# UART5 register map
Registers from a debugger description file.
Registers are 32-bit, access not given, no defined reset value unless marked. A register's access mark holds for its fields unless they carry their own. Addresses are absolute; registers are grouped by the start of their names; lines under a group give offsets from that group; [hi:lo] are bit positions; {n}, {i} and the like mark numbered series; 'fields as' and 'values as' point back to an identical list; <NAME> marks a mode.

## UART5
0x50001000 UART5/DLL
  [7:0] DLL
0x50001000 UART5/THR
  [7:0] THR
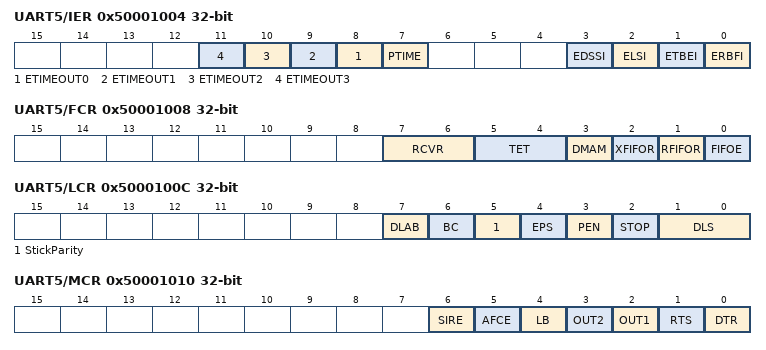
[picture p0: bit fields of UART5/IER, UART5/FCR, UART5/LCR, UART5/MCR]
0x50001004 UART5/IER
  [n+8] ETIMEOUT{n} (n=0..3), [7] PTIME, [3] EDSSI, [2] ELSI, [1] ETBEI, [0] ERBFI
0x50001004 UART5/DLH
  [7:0] DLH
0x50001008 UART5/FCR
  [7:6] RCVR, [5:4] TET, [3] DMAM, [2] XFIFOR, [1] RFIFOR, [0] FIFOE
0x5000100C UART5/LCR
  [7] DLAB, [6] BC, [5] StickParity, [4] EPS, [3] PEN, [2] STOP, [1:0] DLS
0x50001010 UART5/MCR
  [6] SIRE, [5] AFCE, [4] LB, [3] OUT2, [2] OUT1, [1] RTS, [0] DTR
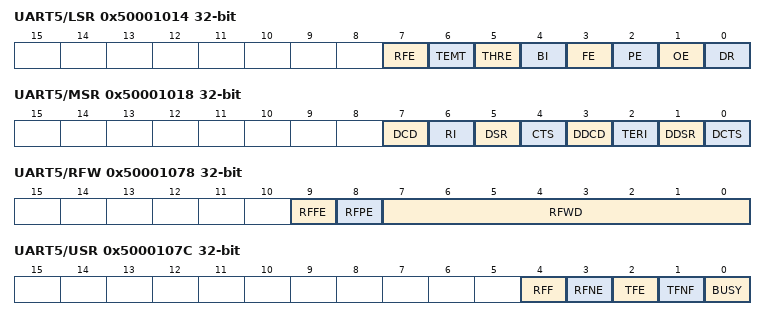
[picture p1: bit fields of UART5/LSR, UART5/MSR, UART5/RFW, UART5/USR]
0x50001014 UART5/LSR ro
  [7] RFE, [6] TEMT, [5] THRE, [4] BI, [3] FE, [2] PE, [1] OE, [0] DR
0x50001018 UART5/MSR ro
  [7] DCD, [6] RI, [5] DSR, [4] CTS, [3] DDCD, [2] TERI, [1] DDSR, [0] DCTS
0x5000101C UART5/SCR
  [7:0] SCR
0x50001030 UART5/STHR
  [7:0] STHR
0x50001070 UART5/FAR
  [0] FAR
0x50001074 UART5/TFR ro
  [7:0] TFR
0x50001078 UART5/RFW
  [9] RFFE, [8] RFPE, [7:0] RFWD
0x5000107C UART5/USR ro
  [4] RFF, [3] RFNE, [2] TFE, [1] TFNF, [0] BUSY
0x50001080 UART5/TFL ro
  [4:0] TFL
0x50001084 UART5/RFL ro
  [4:0] RFL
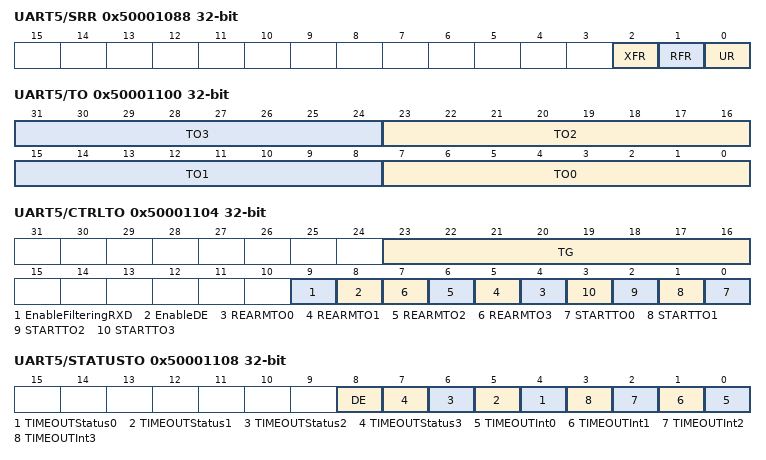
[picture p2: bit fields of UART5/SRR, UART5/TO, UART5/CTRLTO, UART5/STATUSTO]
0x50001088 UART5/SRR
  [2] XFR, [1] RFR, [0] UR
0x5000108C UART5/SRTS
  [0] SRTS
0x50001090 UART5/SBCR
  [0] SBCR
0x50001098 UART5/SFE
  [0] SFE
0x5000109C UART5/SRT
  [1:0] SRCVR
0x500010A0 UART5/STET
  [1:0] STET
0x500010A4 UART5/HTX
  [0] HTX
0x500010A8 UART5/DMASA
  [0] DMASA
0x500010F8 UART5/UCV ro
  [31:0] Version
0x500010FC UART5/CTR ro
  [31:0] ID
0x50001100 UART5/TO
  [8n+7:8n] TO{n} (n=0..3)
0x50001104 UART5/CTRLTO
  [23:16] TG, [9] EnableFilteringRXD, [8] EnableDE, [n+4] REARMTO{n} (n=0..3), [n] STARTTO{n} (n=0..3)
0x50001108 UART5/STATUSTO
  [8] DE, [n+4] TIMEOUTStatus{n} (n=0..3), [n] TIMEOUTInt{n} (n=0..3)
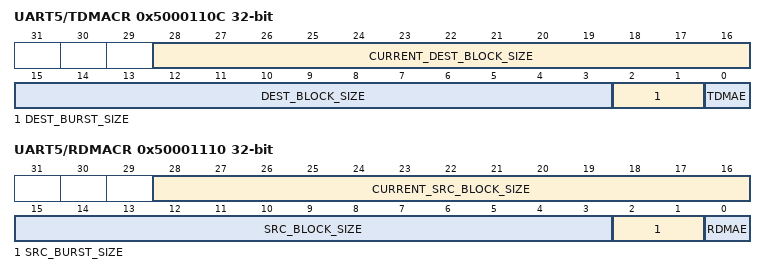
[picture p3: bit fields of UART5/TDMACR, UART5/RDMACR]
0x5000110C UART5/TDMACR
  [28:16] CURRENT_DEST_BLOCK_SIZE, [15:3] DEST_BLOCK_SIZE, [2:1] DEST_BURST_SIZE, [0] TDMAE
0x50001110 UART5/RDMACR
  [28:16] CURRENT_SRC_BLOCK_SIZE, [15:3] SRC_BLOCK_SIZE, [2:1] SRC_BURST_SIZE, [0] RDMAE
